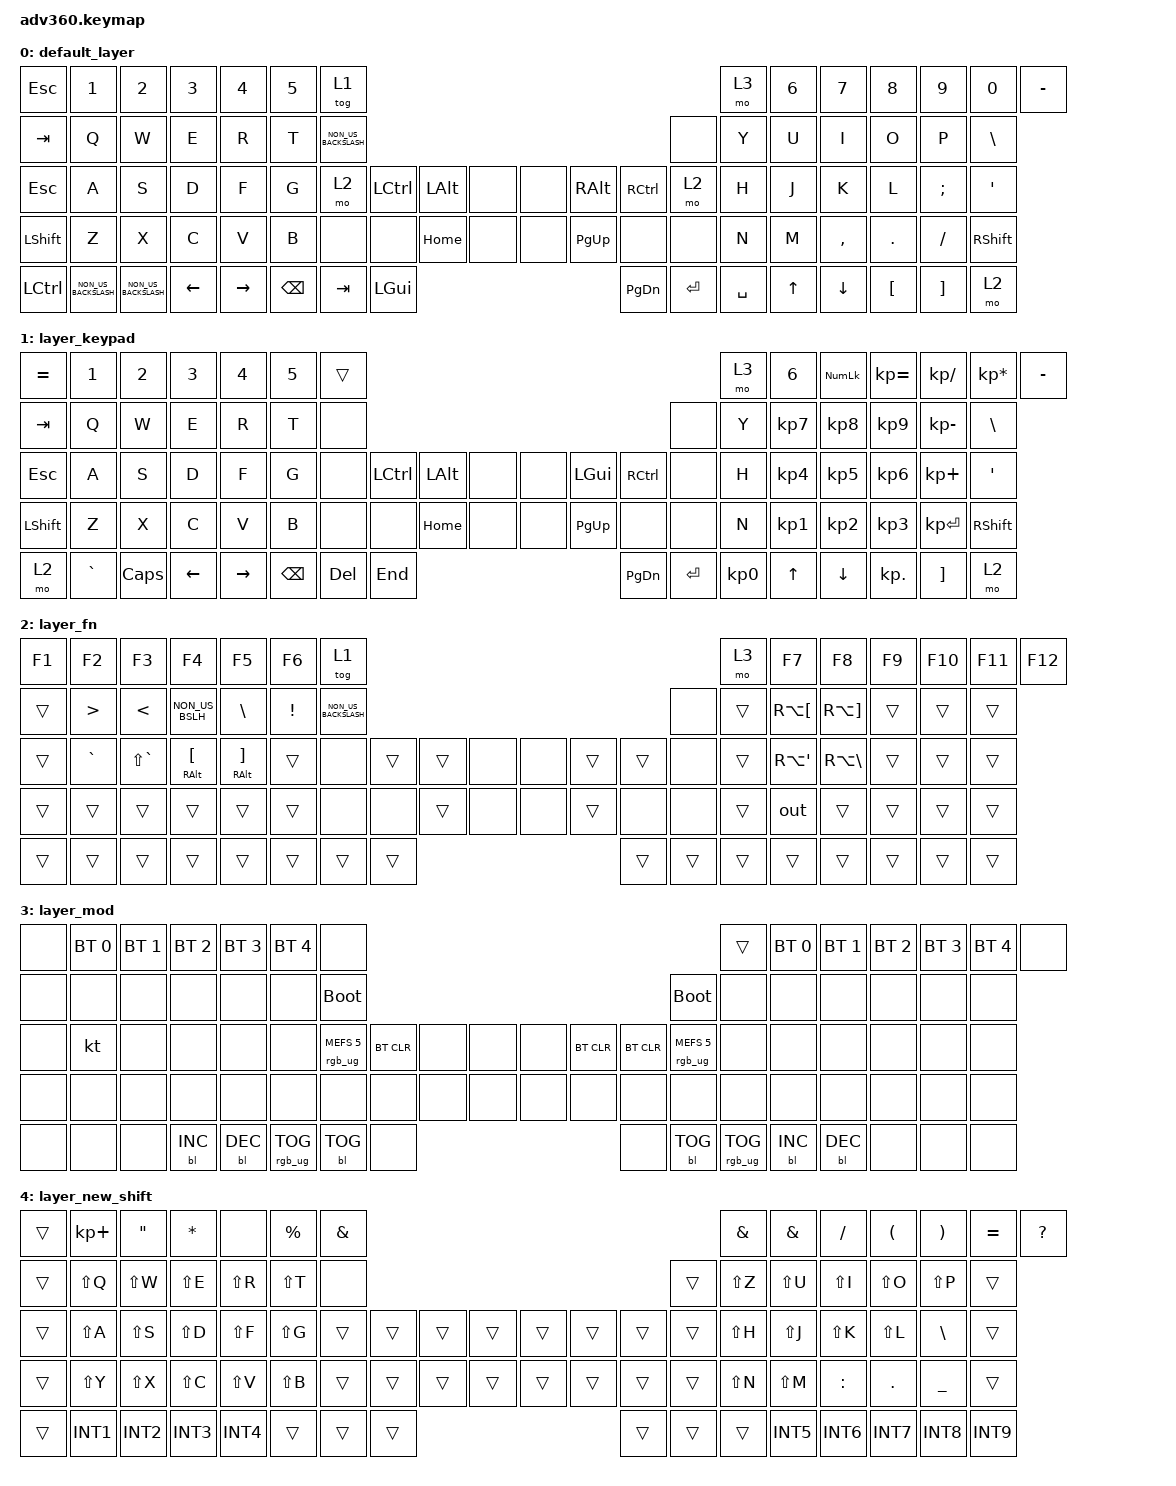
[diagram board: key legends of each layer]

/*
 * Copyright (c) 2020 The ZMK Contributors
 *
 * SPDX-License-Identifier: MIT
 */


/* THIS FILE WAS GENERATED!
 *
 * This file was generated automatically. You may or may not want to
 * edit it directly.
 */

#include <behaviors.dtsi>
#include <dt-bindings/zmk/keys.h>
#include <dt-bindings/zmk/outputs.h>
#include <dt-bindings/zmk/bt.h>
#include <dt-bindings/zmk/keys.h>
#include <dt-bindings/zmk/rgb.h>
#include <dt-bindings/zmk/backlight.h>

/ {
  behaviors {
    #include "macros.dtsi"

    hm: homerow_mods {
        compatible = "zmk,behavior-hold-tap";
        label = "HOMEROW_MODS";
        #binding-cells = <2>;
        tapping-term-ms = <200>;
        quick_tap_ms = <175>;
        flavor = "tap-preferred";
        bindings = <&kp>, <&kp>;
    };
  };

    keymap {
        compatible = "zmk,keymap";


        default_layer {
            bindings = <
     &kp ESCAPE                &kp N1                &kp N2    &kp N3     &kp N4  &kp N5                          &tog 1                                                                     &mo 3  &kp N6  &kp N7     &kp N8    &kp N9    &kp N0  &kp MINUS
        &kp TAB                 &kp Q                 &kp W     &kp E      &kp R   &kp T            &kp NON_US_BACKSLASH                                                                     &none   &kp Y   &kp U      &kp I     &kp O     &kp P   &kp BSLH
        &kp ESC                 &kp A                 &kp S     &kp D      &kp F   &kp G                           &mo 2  &kp LCTRL  &kp LALT   &none   &none  &kp RIGHT_ALT  &kp RCTRL      &mo 2   &kp H   &kp J      &kp K     &kp L  &kp SEMI    &kp SQT
 &kp LEFT_SHIFT                 &kp Z                 &kp X     &kp C      &kp V   &kp B                           &none      &none  &kp HOME   &none   &none      &kp PG_UP      &none      &none   &kp N   &kp M  &kp COMMA   &kp DOT  &kp FSLH  &kp RSHFT
      &kp LCTRL  &kp NON_US_BACKSLASH  &kp NON_US_BACKSLASH  &kp LEFT  &kp RIGHT                                &kp BSPC    &kp TAB  &kp LGUI                      &kp PG_DN  &kp ENTER  &kp SPACE          &kp UP   &kp DOWN  &kp LBKT  &kp RBKT      &mo 2
            >;
        };

        layer_keypad {
            bindings = <
 &kp EQUAL     &kp N1    &kp N2    &kp N3     &kp N4  &kp N5              &trans                                                                 &mo 3  &kp N6  &kp KP_NUM  &kp KP_EQUAL  &kp KP_DIVIDE  &kp KP_MULTIPLY  &kp MINUS
   &kp TAB      &kp Q     &kp W     &kp E      &kp R   &kp T               &none                                                                 &none   &kp Y   &kp KP_N7     &kp KP_N8      &kp KP_N9     &kp KP_MINUS   &kp BSLH
   &kp ESC      &kp A     &kp S     &kp D      &kp F   &kp G               &none  &kp LCTRL  &kp LALT   &none   &none   &kp LGUI  &kp RCTRL      &none   &kp H   &kp KP_N4     &kp KP_N5      &kp KP_N6      &kp KP_PLUS    &kp SQT
 &kp LSHFT      &kp Z     &kp X     &kp C      &kp V   &kp B               &none      &none  &kp HOME   &none   &none  &kp PG_UP      &none      &none   &kp N   &kp KP_N1     &kp KP_N2      &kp KP_N3     &kp KP_ENTER  &kp RSHFT
     &mo 2  &kp GRAVE  &kp CAPS  &kp LEFT  &kp RIGHT                    &kp BSPC    &kp DEL   &kp END                  &kp PG_DN  &kp ENTER  &kp KP_N0              &kp UP      &kp DOWN     &kp KP_DOT         &kp RBKT      &mo 2
            >;
        };

        layer_fn {
            bindings = <
 &kp F1            &kp F2         &kp F3                 &kp F4                  &kp F5           &kp F6                          &tog 1                                                   &mo 3  &kp F7              &kp F8             &kp F9  &kp F10  &kp F11  &kp F12
 &trans  &kp GREATER_THAN         &kp LT        &kp NON_US_BSLH           &kp BACKSLASH  &kp EXCLAMATION            &kp NON_US_BACKSLASH                                                   &none  &trans       &kp RA(LBKT)  &kp RA(RBKT)   &trans   &trans   &trans
 &trans         &kp GRAVE  &kp LS(GRAVE)  &mt RALT LEFT_BRACKET  &mt RALT RIGHT_BRACKET           &trans                           &none  &trans  &trans   &none   &none  &trans  &trans   &none  &trans  &kp RA(SQT)       &kp RA(BACKSLASH)   &trans   &trans   &trans
 &trans            &trans         &trans                 &trans                  &trans           &trans                           &none   &none  &trans   &none   &none  &trans   &none   &none  &trans                &out             &trans   &trans   &trans   &trans
 &trans            &trans         &trans                 &trans                  &trans                                           &trans  &trans  &trans                  &trans  &trans  &trans                      &trans             &trans   &trans   &trans   &trans
            >;
        };

        layer_mod {
            bindings = <
  &none  &bt BT_SEL 0  &bt BT_SEL 1  &bt BT_SEL 2  &bt BT_SEL 3  &bt BT_SEL 4                             &none                                                                              &trans  &bt BT_SEL 0  &bt BT_SEL 1  &bt BT_SEL 2  &bt BT_SEL 3  &bt BT_SEL 4   &none
  &none         &none         &none         &none         &none         &none                       &bootloader                                                                         &bootloader         &none         &none         &none         &none         &none   &none
  &none           &kt         &none         &none         &none         &none            &rgb_ug RGB_MEFS_CMD 5  &bt BT_CLR   &none   &none   &none  &bt BT_CLR  &bt BT_CLR  &rgb_ug RGB_MEFS_CMD 5         &none         &none         &none         &none         &none   &none
  &none         &none         &none         &none         &none         &none                             &none       &none   &none   &none   &none       &none       &none                   &none         &none         &none         &none         &none         &none   &none
  &none         &none         &none    &bl BL_INC    &bl BL_DEC                                 &rgb_ug RGB_TOG  &bl BL_TOG   &none                       &none  &bl BL_TOG         &rgb_ug RGB_TOG                  &bl BL_INC    &bl BL_DEC         &none         &none   &none
            >;
        };

        layer_new_shift {
            bindings = <
 &trans  &kp KP_PLUS  &kp DOUBLE_QUOTES  &kp ASTERISK      &none  &kp PERCENT            &kp AMPERSAND                                                  &kp AMPERSAND   &kp AMPS  &kp SLASH  &kp LEFT_PARENTHESIS  &kp RIGHT_PARENTHESIS       &kp EQUAL  &kp QUESTION
 &trans    &kp LS(Q)          &kp LS(W)     &kp LS(E)  &kp LS(R)    &kp LS(T)                    &none                                                         &trans  &kp LS(Z)  &kp LS(U)             &kp LS(I)              &kp LS(O)       &kp LS(P)        &trans
 &trans    &kp LS(A)          &kp LS(S)     &kp LS(D)  &kp LS(F)    &kp LS(G)                   &trans  &trans  &trans  &trans  &trans  &trans  &trans         &trans  &kp LS(H)  &kp LS(J)             &kp LS(K)              &kp LS(L)   &kp BACKSLASH        &trans
 &trans    &kp LS(Y)          &kp LS(X)     &kp LS(C)  &kp LS(V)    &kp LS(B)                   &trans  &trans  &trans  &trans  &trans  &trans  &trans         &trans  &kp LS(N)  &kp LS(M)             &kp COLON             &kp PERIOD  &kp UNDERSCORE        &trans
 &trans     &kp INT1           &kp INT2      &kp INT3   &kp INT4                                &trans  &trans  &trans                  &trans  &trans         &trans              &kp INT5              &kp INT6               &kp INT7        &kp INT8      &kp INT9
            >;
        };

    };
};
